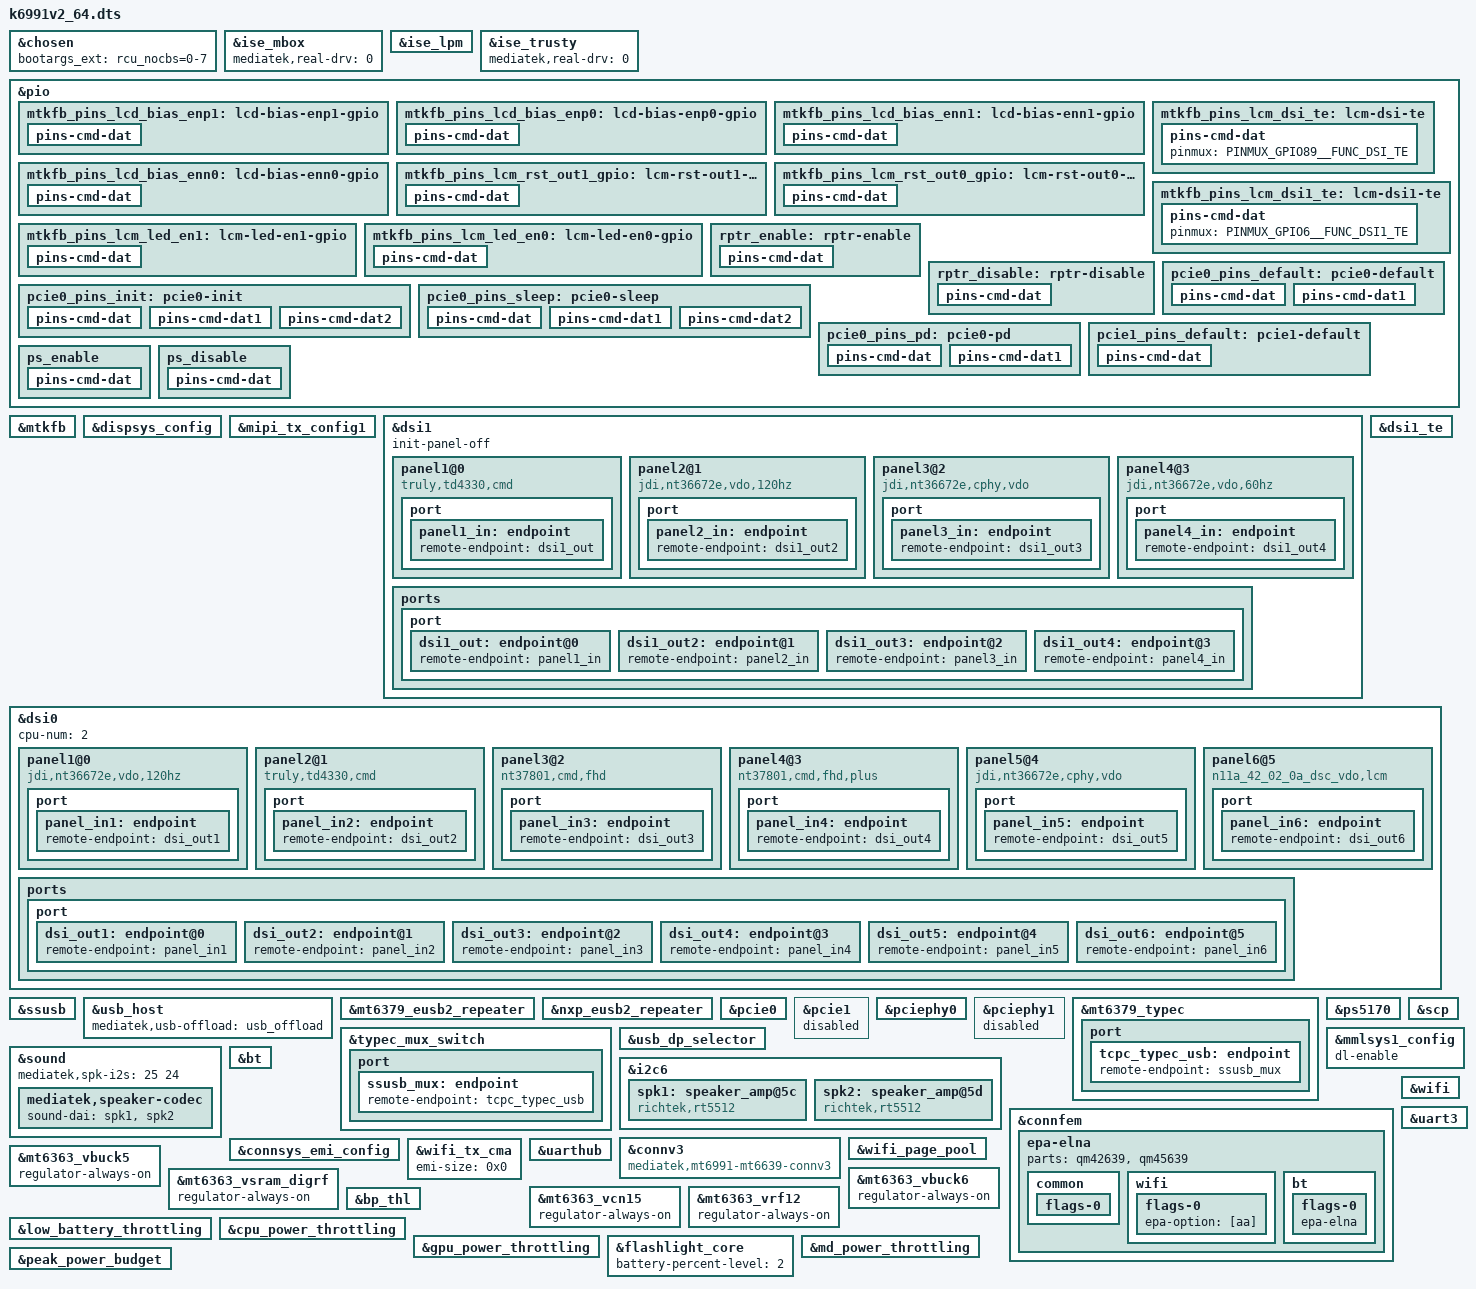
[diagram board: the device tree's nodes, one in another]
// SPDX-License-Identifier: (GPL-2.0 OR MIT)
/*
 * Copyright (C) 2022 MediaTek Inc.
 */
/dts-v1/;
/plugin/;
#include <dt-bindings/clock/mt6991-clk.h>
#include <dt-bindings/interrupt-controller/arm-gic.h>
#include <dt-bindings/interrupt-controller/irq.h>
#include <dt-bindings/phy/phy.h>
#include <dt-bindings/pinctrl/mt6991-pinfunc.h>
#include <dt-bindings/power/mt6991-power.h>

&chosen {
bootargs_ext = "rcu_nocbs=0-7";
};

&ise_mbox {
	mediatek,real-drv = <0>;
};

&ise_lpm {
	ise-wakelock = <0>;
	ise-lpm-freerun = <0>;
	ise-lpm-deinit-bypass = <0>;
	power-domains = <&scpsys MT6991_POWER_DOMAIN_SSR>;
};

&ise_trusty {
	mediatek,real-drv = <0>;
};

&pio {
	mtkfb_pins_lcd_bias_enp1: lcd-bias-enp1-gpio {
		pins-cmd-dat {
			pinmux = <PINMUX_GPIO103__FUNC_GPIO103>;
			slew-rate = <1>;
			output-high;
		};
	};

	mtkfb_pins_lcd_bias_enp0: lcd-bias-enp0-gpio {
		pins-cmd-dat {
			pinmux = <PINMUX_GPIO103__FUNC_GPIO103>;
			slew-rate = <1>;
			output-low;
		};
	};

	mtkfb_pins_lcd_bias_enn1: lcd-bias-enn1-gpio {
		pins-cmd-dat {
			pinmux = <PINMUX_GPIO103__FUNC_GPIO103>;
			slew-rate = <1>;
			output-high;
		};
	};

	mtkfb_pins_lcd_bias_enn0: lcd-bias-enn0-gpio {
		pins-cmd-dat {
			pinmux = <PINMUX_GPIO103__FUNC_GPIO103>;
			slew-rate = <1>;
			output-low;
		};
	};

	mtkfb_pins_lcm_rst_out1_gpio: lcm-rst-out1-gpio {
		pins-cmd-dat {
			pinmux = <PINMUX_GPIO90__FUNC_GPIO90>;
			slew-rate = <1>;
			output-high;
		};
	};

	mtkfb_pins_lcm_rst_out0_gpio: lcm-rst-out0-gpio {
		pins-cmd-dat {
			pinmux = <PINMUX_GPIO90__FUNC_GPIO90>;
			slew-rate = <1>;
			output-low;
		};
	};
	mtkfb_pins_lcm_dsi_te: lcm-dsi-te {
		pins-cmd-dat {
			pinmux = <PINMUX_GPIO89__FUNC_DSI_TE>;
		};
	};

	mtkfb_pins_lcm_led_en1: lcm-led-en1-gpio {
		pins-cmd-dat {
			pinmux = <PINMUX_GPIO174__FUNC_GPIO174>;
			slew-rate = <1>;
			output-high;
		};
	};

	mtkfb_pins_lcm_led_en0: lcm-led-en0-gpio {
		pins-cmd-dat {
			pinmux = <PINMUX_GPIO174__FUNC_GPIO174>;
			slew-rate = <1>;
			output-low;
		};
	};

	mtkfb_pins_lcm_dsi1_te: lcm-dsi1-te {
		pins-cmd-dat {
			pinmux = <PINMUX_GPIO6__FUNC_DSI1_TE>;
		};
	};
};

&mtkfb {
	pinctrl-names = "lcd_bias_enp1_gpio", "lcd_bias_enp0_gpio",
		"lcd_bias_enn1_gpio", "lcd_bias_enn0_gpio",
		"lcm_rst_out1_gpio", "lcm_rst_out0_gpio",
		"mode_te_te", "lcm_led_en1_gpio", "lcm_led_en0_gpio",
		"mode_te_te1";
	pinctrl-0 = <&mtkfb_pins_lcd_bias_enp1>;
	pinctrl-1 = <&mtkfb_pins_lcd_bias_enp0>;
	pinctrl-2 = <&mtkfb_pins_lcd_bias_enn1>;
	pinctrl-3 = <&mtkfb_pins_lcd_bias_enn0>;
	pinctrl-4 = <&mtkfb_pins_lcm_rst_out1_gpio>;
	pinctrl-5 = <&mtkfb_pins_lcm_rst_out0_gpio>;
	pinctrl-6 = <&mtkfb_pins_lcm_dsi_te>;
	pinctrl-7 = <&mtkfb_pins_lcm_led_en1>;
	pinctrl-8 = <&mtkfb_pins_lcm_led_en0>;
	pinctrl-9 = <&mtkfb_pins_lcm_dsi1_te>;

	status = "okay";
};

&dispsys_config {
	pinctrl-names = "mode_te_te", "mode_te_te1";
	pinctrl-0 = <&mtkfb_pins_lcm_dsi_te>;
	pinctrl-1 = <&mtkfb_pins_lcm_dsi1_te>;

	status = "okay";
//	enable-discrete-path = <1>;
	bypass-pc-path = <1>;

	helper-name-proj = "MTK_DRM_OPT_IDLEMGR_DISABLE_ROUTINE_IRQ",
		"MTK_DRM_OPT_MML_DL_SUB_CFG_CLINET",
		"MTK_DRM_OPT_OVL_WCG",
		"MTK_DRM_OPT_OVL_WCG_BY_COLOR_MODE",
		"MTK_DRM_OPT_DSI_UNDERRUN_AEE";

	helper-value-proj = <1>, /*MTK_DRM_OPT_IDLEMGR_DISABLE_ROUTINE_IRQ*/
		<1>, /*MTK_DRM_OPT_MML_DL_SUB_CFG_CLINET*/
		<1>, /*MTK_DRM_OPT_OVL_WCG*/
		<1>, /*MTK_DRM_OPT_OVL_WCG_BY_COLOR_MODE*/
		<1>; /*MTK_DRM_OPT_DSI_UNDERRUN_AEE*/
};

&mipi_tx_config1 {
//	status = "okay";
};

&dsi1 {
//	status = "okay";
	#address-cells = <1>;
	#size-cells = <0>;
	init-panel-off;
	panel1@0 {
		compatible = "truly,td4330,cmd";
		reg = <0>;
		pm-enable-gpios = <&pio 215 0>;
		reset-gpios = <&pio 5 0>;
		swap-from-dts;
		lane-swap-setting = <1 2 0 3 4 2>;
		pn-swap-setting = <1 1 1 1 1 1>;
		gate-ic = <4831>;
		pinctrl-names = "default";
		port {
			panel1_in: endpoint {
				remote-endpoint = <&dsi1_out>;
			};
		};
	};
	panel2@1 {
		compatible = "jdi,nt36672e,vdo,120hz";
		reg = <1>;
		pm-enable-gpios = <&pio 215 0>;
		reset-gpios = <&pio 5 0>;
		gate-ic = <4831>;
		pinctrl-names = "default";
		port {
			panel2_in: endpoint {
				remote-endpoint = <&dsi1_out2>;
			};
		};
	};
	panel3@2 {
		compatible = "jdi,nt36672e,cphy,vdo";
		reg = <2>;
		pm-enable-gpios = <&pio 215 0>;
		reset-gpios = <&pio 5 0>;
		gate-ic = <4831>;
		pinctrl-names = "default";
		port {
			panel3_in: endpoint {
				remote-endpoint = <&dsi1_out3>;
			};
		};
	};
	panel4@3 {
		compatible = "jdi,nt36672e,vdo,60hz";
		reg = <3>;
		pm-enable-gpios = <&pio 215 0>;
		reset-gpios = <&pio 5 0>;
		gate-ic = <4831>;
		pinctrl-names = "default";
		port {
			panel4_in: endpoint {
				remote-endpoint = <&dsi1_out4>;
			};
		};
	};
	ports {
		port {
			dsi1_out: endpoint@0 {
				remote-endpoint = <&panel1_in>;
			};

			dsi1_out2: endpoint@1 {
				remote-endpoint = <&panel2_in>;
			};

			dsi1_out3: endpoint@2 {
				remote-endpoint = <&panel3_in>;
			};

			dsi1_out4: endpoint@3 {
				remote-endpoint = <&panel4_in>;
			};
		};
	};
};

&dsi1_te {
	interrupt-parent = <&pio>;
	interrupts = <6 1 6 1>;
	status = "okay";
};

&dsi0 {
	status = "okay";
	#address-cells = <1>;
	#size-cells = <0>;
	cpu-num = <2>;
	panel1@0 {
		compatible = "jdi,nt36672e,vdo,120hz";
		reg = <0>;
		pm-enable-gpios = <&pio 174 0>;
		reset-gpios = <&pio 90 0>;
		res-switch = <2>;
		gate-ic = <4831>;
		pinctrl-names = "default";
		port {
			panel_in1: endpoint {
			remote-endpoint = <&dsi_out1>;
			};
		};
	};
	panel2@1 {
		compatible = "truly,td4330,cmd";
		reg = <1>;
		pm-enable-gpios = <&pio 174 0>;
		reset-gpios = <&pio 90 0>;
		gate-ic = <4831>;
		pinctrl-names = "default";
		port {
			panel_in2: endpoint {
			remote-endpoint = <&dsi_out2>;
			};
		};
	};
	panel3@2 {
		compatible = "nt37801,cmd,fhd";
		reg = <2>;
		pm-enable-gpios = <&pio 174 0>;
		reset-gpios = <&pio 90 0>;
		res-switch = <2>;
		gate-ic = <4831>;
		pinctrl-names = "default";
		port {
			panel_in3: endpoint {
			remote-endpoint = <&dsi_out3>;
			};
		};
	};
	panel4@3 {
		compatible = "nt37801,cmd,fhd,plus";
		reg = <3>;
		pm-enable-gpios = <&pio 174 0>;
		reset-gpios = <&pio 90 0>;
		res-switch = <2>;
		gate-ic = <4831>;
		pinctrl-names = "default";
		port {
			panel_in4: endpoint {
			remote-endpoint = <&dsi_out4>;
			};
		};
	};
	panel5@4 {
		compatible = "jdi,nt36672e,cphy,vdo";
		reg = <4>;
		pm-enable-gpios = <&pio 174 0>;
		reset-gpios = <&pio 90 0>;
		res-switch = <2>;
		gate-ic = <4831>;
		pinctrl-names = "default";
		port {
			panel_in5: endpoint {
			remote-endpoint = <&dsi_out5>;
			};
		};
	};
	panel6@5 {
		compatible = "n11a_42_02_0a_dsc_vdo,lcm";
		reg = <5>;
		pm-enable-gpios = <&pio 174 0>;
		reset-gpios = <&pio 90 0>;
		res-switch = <2>;
		gate-ic = <4831>;
		pinctrl-names = "default";
		port {
			panel_in6: endpoint {
			remote-endpoint = <&dsi_out6>;
			};
		};
	};

	ports {
		port {
			dsi_out1: endpoint@0 {
				remote-endpoint = <&panel_in1>;
			};

			dsi_out2: endpoint@1 {
				remote-endpoint = <&panel_in2>;
			};

			dsi_out3: endpoint@2 {
				remote-endpoint = <&panel_in3>;
			};

			dsi_out4: endpoint@3 {
				remote-endpoint = <&panel_in4>;
			};

			dsi_out5: endpoint@4 {
				remote-endpoint = <&panel_in5>;
			};

			dsi_out6: endpoint@5 {
				remote-endpoint = <&panel_in6>;
			};
		};
	};
};

&pio {
	rptr_enable: rptr-enable {
		pins-cmd-dat {
			pinmux = <PINMUX_GPIO72__FUNC_GPIO72>;
			output-high;
		};
	};

	rptr_disable: rptr-disable {
		pins-cmd-dat {
			pinmux = <PINMUX_GPIO72__FUNC_GPIO72>;
			output-low;
		};
	};
};

&ssusb {
	mediatek,force-vbus;
	mediatek,clk-mgr;
	mediatek,usb3-drd;
	mediatek,uds = <&usb_dp_selector 19>;
	mediatek,eusb2-cm-l1 = <0x474>;
	usb-role-switch;
	status = "okay";
};

&usb_host {
	mediatek,usb-offload = <&usb_offload>;
	status = "okay";
};

&mt6379_eusb2_repeater {
	status = "okay";
};

&nxp_eusb2_repeater {
	pinctrl-names = "enable", "disable";
	pinctrl-0 = <&rptr_enable>;
	pinctrl-1 = <&rptr_disable>;
	status = "okay";
};

&pcie0 {
	pinctrl-names = "init", "default", "sleep", "pd";
	pinctrl-0 = <&pcie0_pins_init>;
	pinctrl-1 = <&pcie0_pins_default>;
	pinctrl-2 = <&pcie0_pins_sleep>;
	pinctrl-3 = <&pcie0_pins_pd>;
	max-link-speed = <3>;
	status = "okay";
};

&pcie1 {
	pinctrl-names = "default";
	pinctrl-0 = <&pcie1_pins_default>;
	max-link-speed = <4>;
	status = "disabled";
};

&pciephy0 {
	status = "okay";
};

&pciephy1 {
	status = "disabled";
};

/* PCIe pinmux start and falcon not use waken */
&pio {
	pcie0_pins_init: pcie0-init {
		pins-cmd-dat {
			pinmux = <PINMUX_GPIO241__FUNC_GPIO241>;
			output-low;
		};

		pins-cmd-dat1 {
			pinmux = <PINMUX_GPIO243__FUNC_GPIO243>;
			bias-pull-up;
			input-enable;
		};

		pins-cmd-dat2 {
			pinmux = <PINMUX_GPIO242__FUNC_GPIO242>;
			bias-pull-down;
			input-enable;
		};
	};

	pcie0_pins_default: pcie0-default {
		pins-cmd-dat {
			pinmux = <PINMUX_GPIO241__FUNC_PCIE_PERSTN>,
				 <PINMUX_GPIO243__FUNC_PCIE_CLKREQN>;
			bias-pull-up;
		};

		pins-cmd-dat1 {
			pinmux = <PINMUX_GPIO242__FUNC_GPIO242>;
			bias-pull-down;
			input-enable;
		};
	};

	pcie0_pins_sleep: pcie0-sleep {
		pins-cmd-dat {
			pinmux = <PINMUX_GPIO241__FUNC_GPIO241>;
			output-low;
		};

		pins-cmd-dat1 {
			pinmux = <PINMUX_GPIO243__FUNC_GPIO243>;
			bias-pull-up;
			input-enable;
		};

		pins-cmd-dat2 {
			pinmux = <PINMUX_GPIO242__FUNC_GPIO242>;
			bias-pull-down;
			input-enable;
		};
	};

	pcie0_pins_pd: pcie0-pd {
		pins-cmd-dat {
			pinmux = <PINMUX_GPIO241__FUNC_GPIO241>;
			output-low;
		};

		pins-cmd-dat1 {
			pinmux = <PINMUX_GPIO243__FUNC_GPIO243>,
				 <PINMUX_GPIO242__FUNC_GPIO242>;
			bias-pull-down;
			input-enable;
		};
	};

	pcie1_pins_default: pcie1-default {
		pins-cmd-dat {
			pinmux = <PINMUX_GPIO145__FUNC_PCIE_WAKEN_1P>,
				 <PINMUX_GPIO146__FUNC_PCIE_PERSTN_1P>,
				 <PINMUX_GPIO147__FUNC_PCIE_CLKREQN_1P>;
			bias-pull-up = <MTK_PUPD_SET_R1R0_01>;
		};
	};
};
/* PCIe pinmux end */

#if 0
/* no need set here, 6686 will control elna automatically */
/* GPS GPIO standardization start */
&pio {
	gps_pins_default: gps_default {
	};
	gps_l1_lna_pins_ol: gps-l1-lna0 {
		pins-cmd-dat {
			pinmux = <PINMUX_GPIO12__FUNC_GPIO12>;
			output-low;
		};
	};
	gps_l1_lna_pins_dsp_ctrl: gps-l1-lna1 {
		pins-cmd-dat {
			pinmux = <PINMUX_GPIO12__FUNC_GPS_L1_ELNA_EN>;
		};
	};
	gps_l1_lna_pins_oh: gps-l1-lna2 {
		pins-cmd-dat {
			pinmux = <PINMUX_GPIO12__FUNC_GPIO12>;
			output-high;
		};
	};
	gps_l5_lna_pins_ol: gps-l5-lna0 {
		pins-cmd-dat {
			pinmux = <PINMUX_GPIO13__FUNC_GPIO13>;
			output-low;
		};
	};
	gps_l5_lna_pins_dsp_ctrl: gps-l5-lna1 {
		pins-cmd-dat {
			pinmux = <PINMUX_GPIO13__FUNC_GPS_L5_ELNA_EN>;
		};
	};
	gps_l5_lna_pins_oh: gps-l5-lna2 {
		pins-cmd-dat {
			pinmux = <PINMUX_GPIO13__FUNC_GPIO13>;
			output-high;
		};
	};
};
&gps {
	pinctrl-names = "default",
		"gps_l1_lna_disable",
		"gps_l1_lna_dsp_ctrl",
		"gps_l1_lna_enable",
		"gps_l5_lna_disable",
		"gps_l5_lna_dsp_ctrl",
		"gps_l5_lna_enable";
	pinctrl-0 = <&gps_pins_default>;
	pinctrl-1 = <&gps_l1_lna_pins_ol>;
	pinctrl-2 = <&gps_l1_lna_pins_dsp_ctrl>;
	pinctrl-3 = <&gps_l1_lna_pins_oh>;
	pinctrl-4 = <&gps_l5_lna_pins_ol>;
	pinctrl-5 = <&gps_l5_lna_pins_dsp_ctrl>;
	pinctrl-6 = <&gps_l5_lna_pins_oh>;
	status = "okay";
};
/* GPS GPIO standardization end */
#endif

/* usb typec mux start */
&pio {

	ps_enable: ps_enable {
		pins-cmd-dat {
			pinmux = <PINMUX_GPIO207__FUNC_GPIO207>;
			output-high;
		};
	};

	ps_disable: ps_disable {
		pins-cmd-dat {
			pinmux = <PINMUX_GPIO207__FUNC_GPIO207>;
			output-low;
		};
	};

};

&mt6379_typec {
	port {
		tcpc_typec_usb: endpoint {
			remote-endpoint = <&ssusb_mux>;
		};
	};
};

&typec_mux_switch {
	orientation-switch;
	mode-switch;
	accessory;
	port {
		ssusb_mux: endpoint {
			remote-endpoint = <&tcpc_typec_usb>;
		};
	};
};

&ps5170 {
	pinctrl-names = "enable", "disable";
	pinctrl-0 = <&ps_enable>;
	pinctrl-1 = <&ps_disable>;
	status = "okay";
};

&usb_dp_selector {
	status = "okay";
};
/* usb typec mux end */

&scp {
	/* id, mbox, send_size*/
	send-table =
	< 0 0  11>,/* IPI_OUT_AUDIO_VOW_1 */
	//<24 0  6>,/* IPI_OUT_SCP_MPOOL_1 */
	<17 1  6>,/* IPI_OUT_LOGGER_CTRL */
	<29 1 16>,/* IPI_OUT_SENSOR_CTRL */
	<31 1  7>,/* IPI_OUT_SENSOR_NOTIFY */
	< 4 2  1>,/* IPI_OUT_DVFS_SET_FREQ_0 */
	< 5 2  2>,/* IPI_OUT_C_SLEEP_0 */
	< 6 2  1>,/* IPI_OUT_TEST_0 */
	//<11 2  6>,/* IPI_OUT_SCP_MPOOL_0 */
	<33 2  16>,/* IPI_OUT_SCP_CONNSYS */
	< 3 3  4>,/* IPI_OUT_APCCCI_0 */
	<37 3  1>,/* IPI_OUT_SCP_AOD */
	<26 3  9>,/* IPI_OUT_AUDIO_ULTRA_SND_0 */
	<35 3  2>,/* IPI_OUT_C_SCP_HWVOTER_DEBUG */
	<45 3  1>,/* IPI_OUT_SCP_PM_NOTIFY_0 */
	<47 3  2>,/* IPI_PIN_HOST_SCP_CHRE */
	<48 3  2>,/* IPI_PIN_SCP_HOST_CHRE */
	<39 4  4>,/* IPI_OUT_AOV_SCP */
	<43 4  4>,/* IPI_OUT_NPU_SCP */
	<14 4  1>,/* IPI_OUT_DVFS_SET_FREQ_1 */
	<15 4  2>,/* IPI_OUT_C_SLEEP_1 */
	<16 4  1>,/* IPI_OUT_TEST_1 */
	<18 4  2>,/* IPI_OUT_SCPCTL_1 */
	<46 4  1>;/* IPI_OUT_SCP_PM_NOTIFY_1 */
};

&i2c6 {
	spk1: speaker_amp@5c {
		compatible = "richtek,rt5512";
		#sound-dai-cells = <0>;
		reg = <0x5c>;
		status = "okay";
		sound-name-prefix = "Left";
	};

	spk2: speaker_amp@5d {
		compatible = "richtek,rt5512";
		#sound-dai-cells = <0>;
		reg = <0x5d>;
		status = "okay";
		sound-name-prefix = "Right";
	};
};

&sound {
	mediatek,spk-i2s = <25 24>;
	mediatek,speaker-codec {
		sound-dai = <&spk1>, <&spk2>;
	};
};

&mmlsys1_config {
	dl-enable;
};

#if 0
&pdc {
	pd_vbus_upper_bound = <12000000>;
};
#endif

&connfem {
	/* Support Wifi & BT ePA/eLNA FEM on customer load */
	epa-elna {
		parts = <&qm42639 &qm45639>;
		common {
			flags-0 {
				rx-mode = [35];
				fe-ant-cnt = [81];
				fe-main-bt-share-lp2g = [80];
				fe-conn-spdt = [83];
				fe-reserved = [80];
			};
		};
		wifi {
			flags-0 {
				epa-option = [aa];
				/* open-loop; */
			};
		};
		bt {
			flags-0 {
				/* choose one of: epa-elna/epa/elna/bypass */
				epa-elna;
			};
		};
	};
};

&connv3 {
	compatible = "mediatek,mt6991-mt6639-connv3";
	pinctrl-names = "connsys-pin-pmic-en-default",
		"connsys-pin-pmic-en-set",
		"connsys-pin-pmic-en-clr",
		"connsys-pin-pmic-faultb-default",
		"connsys-pin-pmic-faultb-enable",
		"connsys-combo-gpio-init",
		"connsys-combo-gpio-pre-on",
		"connsys-combo-gpio-on",
		"connsys-pin-por-reset-trigger",
		"connsys-pin-por-reset-done";
	pinctrl-0 = <&connsys_pin_pmic_en_default>;
	pinctrl-1 = <&connsys_pin_pmic_en_set>;
	pinctrl-2 = <&connsys_pin_pmic_en_clr>;
	pinctrl-3 = <&connsys_pin_pmic_faultb_default>;
	pinctrl-4 = <&connsys_pin_pmic_faultb_enable>;
	pinctrl-5 = <&connsys_combo_gpio_init>;
	pinctrl-6 = <&connsys_combo_gpio_pre_on>;
	pinctrl-7 = <&connsys_combo_gpio_on>;
	pinctrl-8 = <&connsys_pin_por_reset_trigger>;
	pinctrl-9 = <&connsys_pin_por_reset_done>;
};

&bt {
	baudrate = <12000000>;
	flavor-bin = "new9gen2";
};

&connsys_emi_config {
	emi-layout-region =
		<0 0x00c00000>, /* 6639 WiFi MCU */
		<1 0x003c0000>, /* Connsys RO */
		<2 0x00085000>, /* Connsys RW */
		<3 0x0004b000>, /* SCP batching data */
		<4 0x00012000>, /* SCP DFD dump */
		<5 0x0000e000>, /* Reserved for alignment */
		<6 0x00040000>, /* Connsys shared data */
		<7 0x00140000>, /* GPS_EMI */
		<8 0x002fa000>, /* MNL/MPE BIN data */
		<9 0x000d6000>, /* Connsys/SCP shared */
		<10 0x000a0000>, /* WF MISC */
		<11 0x01b00000>; /* WFDMA1 */
};

&wifi {
	emi-size = <0x1b00000>;
	flavor-bin = "new9gen2";
};

&wifi_page_pool {
	cma-mem = <1>;
	emi-size = <0x5400000>;
};

&wifi_tx_cma {
	emi-size = <0x0>;
};

&bt {
	baudrate = <12000000>;
	flavor-bin = "new9gen2";
};

&uarthub {
	baud-rate = <0>; /* 0: 12m, 1: 24m */
	wakeup-mode = <0>; /* 0: sw, 1: hw */
};

&uart3 {
	clocks = <&clk104m>, <&pericfg_ao_clk CLK_PERAO_UART3_BCLK_UART>;
	hub-baud = <12000000>;
};

&mt6363_vbuck5 {
	regulator-always-on;
};

&mt6363_vbuck6 {
	regulator-always-on;
};

&mt6363_vsram_digrf {
	regulator-always-on;
};

&mt6363_vcn15 {
	regulator-always-on;
};

&mt6363_vrf12 {
	regulator-always-on;
};

&bp_thl {
	max-throttle-level = <3>;
	soc-throttle-level = <0 0 0 2 2 3>, //temperature stage 0
				<0 0 0 2 2 3>, //temperature stage 1
				<0 0 1 2 2 3>, //temperature stage 2
				<0 1 1 2 3 3>; //temperature stage 3

	soc-max-stage = <5>;
	soc-limit-threshold = <50 40 10 7 5>;

	temperature-max-stage = <3>;
	temperature-stage-threshold = <25 10 0>;
};

&low_battery_throttling {
	throttle-level = <0 1 2 3>,
			<0 1 2 3>,
			<0 1 4 5>,
			<0 1 4 5>;
};

&cpu_power_throttling {
	lbat-max-level = <5>;
	lbat-limit-freq-lv1 = < 2100000  2100000 2100000>;
	lbat-limit-freq-lv2 = < 2000000  2000000 2000000>;
	lbat-limit-freq-lv3 = < 1800000  1800000 1800000>;
	lbat-limit-freq-lv4 = < 1200000  622000  798000>;
	lbat-limit-freq-lv5 = <  339000  662000  798000>;

	soc-max-level = <3>;
	soc-core-active-lv1 = < 1 1 1 1 1 1 1 1 >;
	soc-core-active-lv2 = < 1 1 1 1 1 1 1 1 >;
	soc-core-active-lv3 = < 1 1 1 1 1 1 1 0 >;
	soc-limit-freq-lv1 = < 2147483647  2147483647 2147483647 >;
	soc-limit-freq-lv2 = < 2147483647  2147483647 2147483647 >;
	soc-limit-freq-lv3 = < 1800000 1800000 1800000>;
};

&gpu_power_throttling {
	lbat-max-level = <5>;
	lbat-limit-freq-lv1 = <700000>;
	lbat-limit-freq-lv2 = <550000>;
	lbat-limit-freq-lv3 = <550000>;
	lbat-limit-freq-lv4 = <338000>;
	lbat-limit-freq-lv5 = <338000>;

	soc-max-level = <3>;
	soc-limit-freq-lv1 = <2147483647>;
	soc-limit-freq-lv2 = <2147483647>;
	soc-limit-freq-lv3 = <338000>;
};

&flashlight_core {
	battery-percent-level = <2>;
};

&md_power_throttling {
	lbat-max-level = <5>;
	lbat-reduce-tx-lv1 = <0>;
	lbat-reduce-tx-lv2 = <6>;
	lbat-reduce-tx-lv3 = <6>;
	lbat-reduce-tx-lv4 = <6>;
	lbat-reduce-tx-lv5 = <6>;
};

&peak_power_budget {
	soc-max-level = <3>;
	soc-hpt-ctrl-lv1 = <7>;
	soc-hpt-ctrl-lv2 = <7>;
	soc-hpt-ctrl-lv3 = <0>;

	mincombo-temp-threshold = <10>;
	mincombo-min-combo = <8>;

	//hpt-volt = 0(2.4V), 1(2.6V) 2(2.8V) 3(3.0V) 4(3.2V)
	soc-hpt-volt-lv0 = <2>; //lv0 is high battery level setting
	soc-hpt-volt-lv1 = <2>;
	soc-hpt-volt-lv2 = <2>;
	soc-hpt-volt-lv3 = <2>;

	//ppb-mode = 24(ppb off, hpt(HWPT) can switch scaling factor)
	//           12(ppb on,  hpt(HWPT) can switch scaling factor)
	soc-ppb-mode-lv0 = <24>; //lv0 is high battery level setting
	soc-ppb-mode-lv1 = <12>;
	soc-ppb-mode-lv2 = <12>;
	soc-ppb-mode-lv3 = <12>;
};

#include <k6991v2_64/cust.dtsi>
#include "mediatek/cust_k6991v2_connfem.dtsi"

#include "mediatek/bat_setting/mt6991p_battery_prop.dtsi"
#include "mediatek/cust_mt6991_touch_1080x2400_mult.dtsi"
#include "mediatek/cust_mt6991_camera_v4l2.dtsi"
/*End of this file, DO NOT ADD ANYTHING HERE*/

